# RL6678_IP_SVD register map
Vendor: Realtek
Registers are 32-bit, read-write, reset 0x0 unless marked. A register's access mark holds for its fields unless they carry their own. Offsets are from the block's base; [hi:lo] are bit positions; lines under a group give offsets from that group; {n}, {i} and the like mark numbered series.

## MEM_CTRL
Base 0x42009200
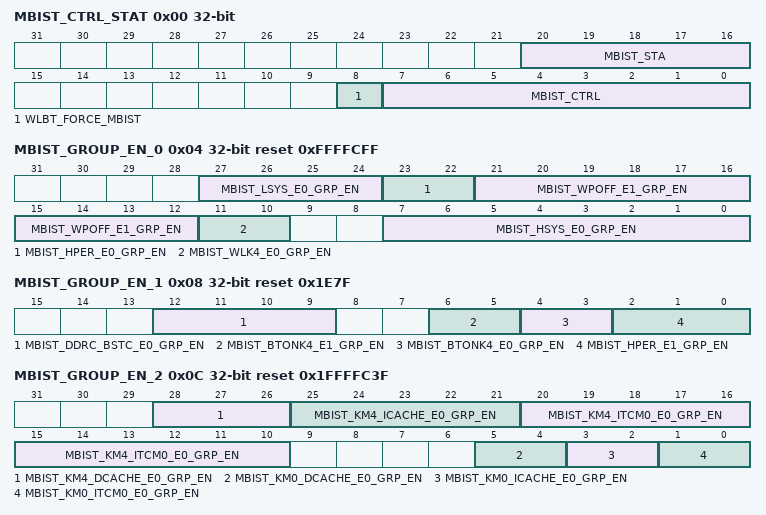
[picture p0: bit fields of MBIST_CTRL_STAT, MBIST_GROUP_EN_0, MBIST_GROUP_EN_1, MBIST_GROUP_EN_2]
0x00 MBIST_CTRL_STAT access per field — MEMx MBIST control and status register
  [20:16] MBIST_STA ro — [16]: MBIST START_PAUSE [17]: MBIST NRML_DONE [18]: MBIST NRML_FAIL [19]: MBIST DRF_DONE [20]: MBIST DRF_FAIL
  [8] WLBT_FORCE_MBIST rw — select power mode signal of BT and WL memory when mbist testing: 1: reg 0: from BT/WL
  [7:0] MBIST_CTRL rw — [0]: MBIST_CLK_EN [1]: MBIST_RSTB_ALL: MEMx bist reset of all memorys. [3:2]: MBIST_MSEL_ALL MEMx mbist method selection of all memorys 2'b01: normal 2'b10: drf 2'b11: normal+drf [4]: MBIST_RESUME [5]: MBIST_RESUME_PS [6]: MBIST_DYN_READ_EN [7]: MBIST_PHYCLK_STOP
0x04 MBIST_GROUP_EN_0 reset 0xFFFFCFF — MEMx system memory group enable control register
  [27:24] MBIST_LSYS_E0_GRP_EN, [23:22] MBIST_HPER_E0_GRP_EN, [21:12] MBIST_WPOFF_E1_GRP_EN, [11:10] MBIST_WLK4_E0_GRP_EN, [7:0] MBIST_HSYS_E0_GRP_EN
0x08 MBIST_GROUP_EN_1 reset 0x1E7F — MEMx system meory group enable control register
  [12:9] MBIST_DDRC_BSTC_E0_GRP_EN, [6:5] MBIST_BTONK4_E1_GRP_EN, [4:3] MBIST_BTONK4_E0_GRP_EN, [2:0] MBIST_HPER_E1_GRP_EN
0x0C MBIST_GROUP_EN_2 reset 0x1FFFFC3F — MEMx system meory group enable control register
  [28:26] MBIST_KM4_DCACHE_E0_GRP_EN, [25:21] MBIST_KM4_ICACHE_E0_GRP_EN, [20:10] MBIST_KM4_ITCM0_E0_GRP_EN, [5:4] MBIST_KM0_DCACHE_E0_GRP_EN, [3:2] MBIST_KM0_ICACHE_E0_GRP_EN, [1:0] MBIST_KM0_ITCM0_E0_GRP_EN
0x10 MBIST_RSTB_0 reset 0xFFFFFFFF — MEMx MBIST reset control register [31:0]
  [31:0] MBIST_RSTB_31_0 — valid MBIST_RSTB range is [MBIST_GRP_NUM-1:0]. MBIST_GRP_NUM = 34, they are: *system memory group: 25 *bt special group: 1 *km0_e0 group : 3 *km4_e0 group : 3 *mipic_e0 group: 2
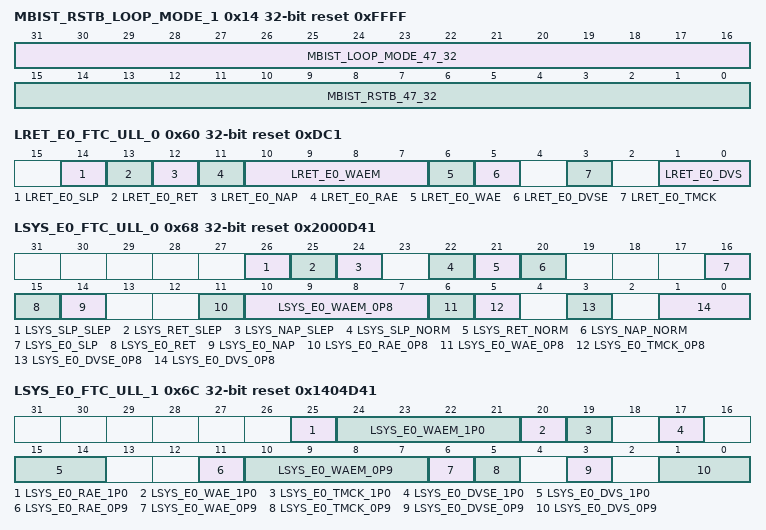
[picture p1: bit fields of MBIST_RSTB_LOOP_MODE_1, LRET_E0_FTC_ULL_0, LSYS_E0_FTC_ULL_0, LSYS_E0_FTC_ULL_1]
0x14 MBIST_RSTB_LOOP_MODE_1 reset 0xFFFF — MEMx MBIST reset & loop_mode control register [47:32]
  [31:16] MBIST_LOOP_MODE_47_32 — valid MBIST_LOOP_MODE range is [MBIST_GRP_NUM-1:0].
  [15:0] MBIST_RSTB_47_32 — valid MBIST_RSTB range is [MBIST_GRP_NUM-1:0]. MBIST_GRP_NUM = 34, they are: *system memory group: 25 *bt special group: 1 *km0_e0 group : 3 *km4_e0 group : 3 *mipic_e0 group: 2
0x18 MBIST_LOOP_MODE_0 — MEMx MBIST loop mode controlregister
  [31:0] MBIST_LOOP_MODE_31_0 — valid MBIST_LOOP_MODE range is [MBIST_GRP_NUM-1:0]
0x1C MBIST_MSEL_0 reset 0xFFFFFFFF — MEMx MBIST method select register control bit[31:0]
  [31:0] MBIST_MSEL_31_0 — valid MBIST_MSEL range is [MBIST_GRP_NUM*2-1:0] MBIST_MSEL[2*X] = 1 eanbles BIST_MODE mode of groupX; MBIST_MSEL[2*X+1] = 1 eanbles DRF_BIST_MODE mode of groupX.
0x20 MBIST_MSEL_1 reset 0xFFFFFFFF — MEMx MBIST method select control register bit[63:32]
  [31:0] MBIST_MSEL_63_32 — valid MBIST_MSEL range is [MBIST_GRP_NUM*2-1:0] MBIST_MSEL[2*X] = 1 eanbles BIST_MODE mode of groupX; MBIST_MSEL[2*X+1] = 1 eanbles DRF_BIST_MODE mode of groupX.
0x24 MBIST_MSEL_2 reset 0xFFFFFFFF — MEMx MBIST method select control register bit[95:64]
  [31:0] MBIST_MSEL_95_64 — valid MBIST_MSEL range is [MBIST_GRP_NUM*2-1:0] MBIST_MSEL[2*X] = 1 eanbles BIST_MODE mode of groupX; MBIST_MSEL[2*X+1] = 1 eanbles DRF_BIST_MODE mode of groupX.
0x28 MBIST_START_PAUSE_STAT ro — MEMx mbist start pause status register
0x2C MBIST_DONE_STAT ro — MEMx MBIST done status register
{0x30+4i} MBIST_FAIL_NRML_STAT_{i} ro (i=0..2) — MEMx MBIST fail status register bit[{32i+31}:{32i}]
  [31:0] MBIST_FAIL_NRML_STAT_{32i+31}_{32i}
{0x3C+4i} MBIST_FAIL_DRF_STAT_{i} ro (i=0..2) — MEMx drf mbist fail status register bit[{32i+31}:{32i}]
  [31:0] MBIST_FAIL_DRF_STAT_{32i+31}_{32i}
0x48 ROM_LSPMC_E0_MISR_DOUT_0 ro — lspmc_e0 ROM mbist misr_dout[31:0]
  [31:0] ROM_LSPMC_E0_MISR_DOUT_31_0
0x4C ROM_LSPMC_E0_MISR_DOUT_1 ro — lspmc_e0 ROM mbist misr_dout[35:32]
  [3:0] ROM_LSPMC_E0_MISR_DOUT_35_32
0x50 ROM_AONPMC_E0_MISR_DOUT_0 ro — aonpmc_e0 ROM mbist misr_dout[31:0]
  [31:0] ROM_AONPMC_E0_MISR_DOUT_31_0
0x54 ROM_AONPMC_E0_MISR_DOUT_1 ro — aonpmc_e0 ROM mbist misr_dout[35:32]
  [3:0] ROM_AONPMC_E0_MISR_DOUT_35_32
0x58 ROM_CA7BOOT_E0_MISR_DOUT_0 ro — catboot_e0 ROM mbist misr_dout[31:0]
  [31:0] ROM_CA7BOOT_E0_MISR_DOUT_31_0
0x5C ROM_CA7BOOT_E0_MISR_DOUT_1 ro — catboot_e0 ROM mbist misr_dout[63:32]
  [31:0] ROM_CA7BOOT_E0_MISR_DOUT_63_32
0x60 LRET_E0_FTC_ULL_0 reset 0xDC1
  [14] LRET_E0_SLP — SW control: SW can write this register when chip is ACTIVE. HW control: will load LSYS_SLP_SLEP to this reg when chip goes to SLEP ; will load LSYS_SLP_NORM to this reg when chip goes to ACTIVE ; SLP = 1 : Shut-down mode
  [13] LRET_E0_RET — SW control: SW can write this register when chip is ACTIVE. HW control: will load LSYS_RET_SLEP to this reg when chip goes to SLEP ; will load LSYS_RET_NORM to this reg when chip goes to ACTIVE ; RET = 1 : Deep-sleep mode
  [12] LRET_E0_NAP — SW control: SW can write this register when chip is ACTIVE. HW control: will load LSYS_NAP_SLEP to this reg when chip goes to SLEP ; will load LSYS_NAP_NORM to this reg when chip goes to ACTIVE ; NAP = 1 : Light-sleep mode
  [11] LRET_E0_RAE — FTC_ULL+ SPRAM RAE, 0.8V
  [10:7] LRET_E0_WAEM — FTC_ULL+ SPRAM WAEM[3:2] @0.8V *WAEM[3:0] @ 0.8V: 4'b1011 *WAEM[3:0] @ 0.9v/1.0v: 4'b1001
  [6] LRET_E0_WAE — FTC_ULL+ SPRAM WAE, 0.8V
  [5] LRET_E0_DVSE — FTC_ULL+ SPRAM DVSE
  [3] LRET_E0_TMCK — FTC_ULL+ SPRAM TMCK
  [1:0] LRET_E0_DVS — FTC_ULL+ DVS default is 2'b01 in 0.8v/0.9v,1.0v.
0x68 LSYS_E0_FTC_ULL_0 reset 0x2000D41
  [26] LSYS_SLP_SLEP — deep sleep mode. SW control: set this register before chip goes to SLEP HW control: when chip goes to SLEP,PMC will load this reg value to LSYS_E0_SLP/LRET_E0_SLP/KM0_DCACHE_DATA_SLP/KM0_DCACHE_TAG_SLP/KM0_ICACHE_DATA_SLP/KM0_ICACHE_TAG_SLP (set_pst_lmem=1 & val_pst_lmem=0)
  [25] LSYS_RET_SLEP — deep sleep mode. SW control: set this register before chip goes to SLEP HW control: when chip goes to SLEP,PMC will load this reg value to LSYS_E0_RET/LRET_E0_RET/KM0_DCACHE_DATA_RET/KM0_DCACHE_TAG_RET/KM0_ICACHE_DATA_RET/KM0_ICACHE_TAG_RET (set_pst_lmem=1 & val_pst_lmem=0)
  [24] LSYS_NAP_SLEP — deep sleep mode. SW control: set this register before chip goes to SLEP HW control: when chip goes to SLEP,PMC will load this reg value to LSYS_E0_NAP/LRET_E0_NAP/KM0_DCACHE_DATA_NAP/KM0_DCACHE_TAG_NAP/KM0_ICACHE_DATA_NAP/KM0_ICACHE_TAG_NAP (set_pst_lmem=1 & val_pst_lmem=0)when chip goes to SLEP
  [22] LSYS_SLP_NORM — Active mode. HW control: when chip goes to ACTIVE, PMC will load this reg value to LSYS_E0_SLP/LRET_E0_SLP/KM0_DCACHE_DATA_SLP/KM0_DCACHE_TAG_SLP/KM0_ICACHE_DATA_SLP/KM0_ICACHE_TAG_SLP (set_pst_lmem=1 & val_pst_lmem=1).
  [21] LSYS_RET_NORM — Active mode. HW control: when chip goes to ACTIVE, PMC will load this reg value to LSYS_E0_RET/LRET_E0_RET/KM0_DCACHE_DATA_RET/KM0_DCACHE_TAG_RET/KM0_ICACHE_DATA_RET/KM0_ICACHE_TAG_RET (set_pst_lmem=1 & val_pst_lmem=1).
  [20] LSYS_NAP_NORM — Active mode. HW control: when chip goes to ACTIVE, PMC will load this reg value to LSYS_E0_NAP/LRET_E0_NAP/KM0_DCACHE_DATA_NAP/KM0_DCACHE_TAG_NAP/KM0_ICACHE_DATA_NAP/KM0_ICACHE_TAG_NAP (set_pst_lmem=1 & val_pst_lmem=1).
  [16] LSYS_E0_SLP — SW control: SW can write this register when chip is ACTIVE. HW control: will load LSYS_SLP_SLEP to this reg when chip goes to SLEP ; will load LSYS_SLP_NORM to this reg when chip goes to ACTIVE ; SLP = 1 : Shut-down mode
  [15] LSYS_E0_RET — SW control: SW can write this register when chip is ACTIVE. HW control: will load LSYS_RET_SLEP to this reg when chip goes to SLEP ; will load LSYS_RET_NORM to this reg when chip goes to ACTIVE ; RET = 1 : Deep-sleep mode
  [14] LSYS_E0_NAP — SW control: SW can write this register when chip is ACTIVE. HW control: will load LSYS_NAP_SLEP to this reg when chip goes to SLEP ; will load LSYS_NAP_NORM to this reg when chip goes to ACTIVE ; NAP = 1 : Light-sleep mode
  [11] LSYS_E0_RAE_0P8 — FTC_ULL+ SPRAM RAE, @0.8V
  [10:7] LSYS_E0_WAEM_0P8 — FTC_ULL+ SPRAM WAEM[3:2], @0.8V *WAEM[3:0] @ 0.8V: 4'b1010 *WAEM[3:0] @ 0.9v/1.0v: 4'b1010
  [6] LSYS_E0_WAE_0P8 — FTC_ULL+ SPRAM WAE, @0.8V
  [5] LSYS_E0_TMCK_0P8 — FTC_ULL+ SPRAM TMCK
  [3] LSYS_E0_DVSE_0P8 — FTC_ULL+ SPRAM DVSE
  [1:0] LSYS_E0_DVS_0P8 — FTC_ULL+ DVS default is 2'b01 in 0.8v/0.9v,1.0v.
0x6C LSYS_E0_FTC_ULL_1 reset 0x1404D41
  [25] LSYS_E0_RAE_1P0 — FTC_ULL+ SPRAM RAE @1.0V
  [24:21] LSYS_E0_WAEM_1P0 — FTC_ULL+ SPRAM WAEM[1:0] @0.9V
  [20] LSYS_E0_WAE_1P0 — *WAEM[3:0] @ 0.8V: 4'b1010
  [19] LSYS_E0_TMCK_1P0 — *WAEM[3:0] @ 0.9v/1.0v: 4'b1010
  [17] LSYS_E0_DVSE_1P0 — FTC_ULL+ SPRAM DVSE
  [15:14] LSYS_E0_DVS_1P0 — FTC_ULL+ DVS default is 2'b01 in 0.8v/0.9v,1.0v.
  [11] LSYS_E0_RAE_0P9 — FTC_ULL+ SPRAM RAE @0.9V
  [10:7] LSYS_E0_WAEM_0P9 — FTC_ULL+ SPRAM WAEM[1:0] @0.9V *WAEM[3:0] @ 0.8V: 4'b1010 *WAEM[3:0] @ 0.9v/1.0v: 4'b1010
  [6] LSYS_E0_WAE_0P9 — FTC_ULL+ SPRAM WAE @0.9V
  [5] LSYS_E0_TMCK_0P9 — FTC_ULL+ SPRAM TMCK
  [3] LSYS_E0_DVSE_0P9 — FTC_ULL+ SPRAM DVSE
  [1:0] LSYS_E0_DVS_0P9 — FTC_ULL+ DVS default is 2'b01 in 0.8v/0.9v,1.0v.
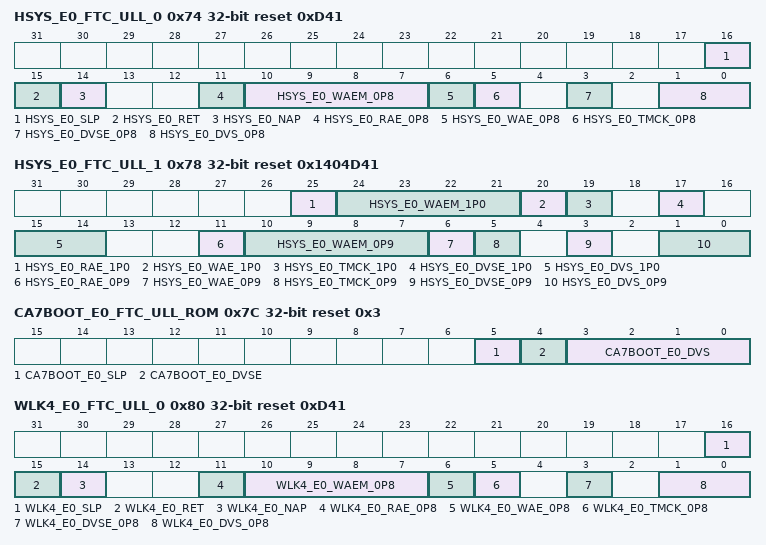
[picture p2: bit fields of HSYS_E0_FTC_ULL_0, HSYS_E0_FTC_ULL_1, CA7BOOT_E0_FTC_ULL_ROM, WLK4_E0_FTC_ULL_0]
0x74 HSYS_E0_FTC_ULL_0 reset 0xD41
  [16] HSYS_E0_SLP — FTC_ULL+ SPRAM SLP
  [15] HSYS_E0_RET — FTC_ULL+ SPRAM RET
  [14] HSYS_E0_NAP — FTC_ULL+ SPRAM NAP
  [11] HSYS_E0_RAE_0P8 — FTC_ULL+ SPRAM RAE, @0.8V
  [10:7] HSYS_E0_WAEM_0P8 — FTC_ULL+ SPRAM WAEM[3:2], @0.8V *WAEM[3:0] @ 0.8V: 4'b1010 *WAEM[3:0] @ 0.9v/1.0v: 4'b1010
  [6] HSYS_E0_WAE_0P8 — FTC_ULL+ SPRAM WAE, @0.8V
  [5] HSYS_E0_TMCK_0P8 — FTC_ULL+ SPRAM TMCK
  [3] HSYS_E0_DVSE_0P8 — FTC_ULL+ SPRAM DVSE
  [1:0] HSYS_E0_DVS_0P8 — FTC_ULL+ DVS default is 2'b01 in 0.8v/0.9v,1.0v.
0x78 HSYS_E0_FTC_ULL_1 reset 0x1404D41
  [25] HSYS_E0_RAE_1P0 — FTC_ULL+ SPRAM RAE @1.0V
  [24:21] HSYS_E0_WAEM_1P0 — FTC_ULL+ SPRAM WAEM[3:2] @1.0V *WAEM[3:0] @ 0.8V: 4'b1010 *WAEM[3:0] @ 0.9v/1.0v: 4'b1010
  [20] HSYS_E0_WAE_1P0 — FTC_ULL+ SPRAM WAE @1.0V
  [19] HSYS_E0_TMCK_1P0 — FTC_ULL+ SPRAM TMCK
  [17] HSYS_E0_DVSE_1P0 — FTC_ULL+ SPRAM DVSE
  [15:14] HSYS_E0_DVS_1P0 — FTC_ULL+ DVS default is 2'b01 in 0.8v/0.9v,1.0v.
  [11] HSYS_E0_RAE_0P9 — FTC_ULL+ SPRAM RAE @0.9V
  [10:7] HSYS_E0_WAEM_0P9 — FTC_ULL+ SPRAM WAEM[1:0] @0.9V *WAEM[3:0] @ 0.8V: 4'b1010 *WAEM[3:0] @ 0.9v/1.0v: 4'b1010
  [6] HSYS_E0_WAE_0P9 — FTC_ULL+ SPRAM WAE @0.9V
  [5] HSYS_E0_TMCK_0P9 — FTC_ULL+ SPRAM TMCK
  [3] HSYS_E0_DVSE_0P9 — FTC_ULL+ SPRAM DVSE
  [1:0] HSYS_E0_DVS_0P9 — FTC_ULL+ DVS default is 2'b01 in 0.8v/0.9v,1.0v.
0x7C CA7BOOT_E0_FTC_ULL_ROM reset 0x3
  [5] CA7BOOT_E0_SLP — FTC_ULL+ SPROM, PG bit2, not used in btrom
  [4] CA7BOOT_E0_DVSE — FTC_ULL+ SPROM
  [3:0] CA7BOOT_E0_DVS — FTC_ULL+ SPROM
0x80 WLK4_E0_FTC_ULL_0 reset 0xD41
  [16] WLK4_E0_SLP — FTC_ULL+ SPRAM SLP
  [15] WLK4_E0_RET — FTC_ULL+ SPRAM RET
  [14] WLK4_E0_NAP — FTC_ULL+ SPRAM NAP
  [11] WLK4_E0_RAE_0P8 — FTC_ULL+ SPRAM RAE, @0.8V
  [10:7] WLK4_E0_WAEM_0P8 — FTC_ULL+ SPRAM WAEM[3:2], @0.8V *WAEM[3:0] @ 0.8V: 4'b1010 *WAEM[3:0] @ 0.9v/1.0v: 4'b1010
  [6] WLK4_E0_WAE_0P8 — FTC_ULL+ SPRAM WAE, @0.8V
  [5] WLK4_E0_TMCK_0P8 — FTC_ULL+ SPRAM TMCK
  [3] WLK4_E0_DVSE_0P8 — FTC_ULL+ SPRAM DVSE
  [1:0] WLK4_E0_DVS_0P8 — FTC_ULL+ DVS default is 2'b01 in 0.8v/0.9v,1.0v.
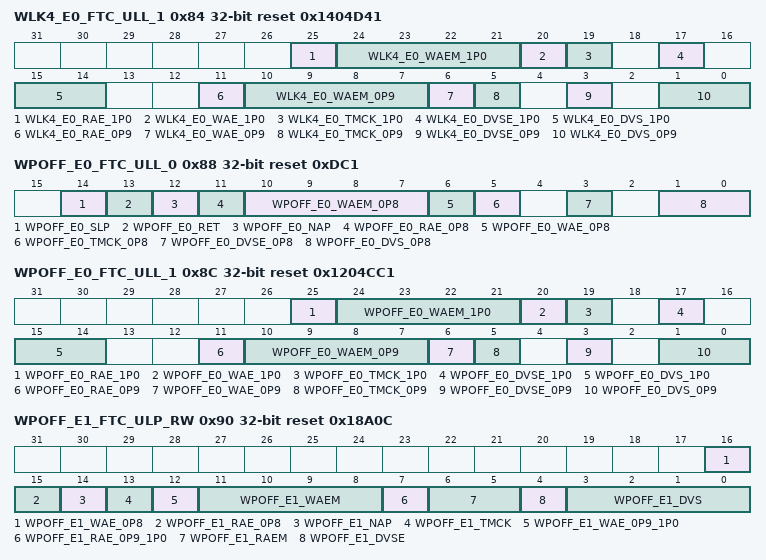
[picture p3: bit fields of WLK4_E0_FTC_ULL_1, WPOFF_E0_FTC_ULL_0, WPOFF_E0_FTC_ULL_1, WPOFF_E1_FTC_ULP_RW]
0x84 WLK4_E0_FTC_ULL_1 reset 0x1404D41
  [25] WLK4_E0_RAE_1P0 — FTC_ULL+ SPRAM RAE @1.0V
  [24:21] WLK4_E0_WAEM_1P0 — FTC_ULL+ SPRAM WAEM[3:2], @0.8V *WAEM[3:0] @ 0.8V: 4'b1010 *WAEM[3:0] @ 0.9v/1.0v: 4'b1010
  [20] WLK4_E0_WAE_1P0 — FTC_ULL+ SPRAM WAE @1.0V
  [19] WLK4_E0_TMCK_1P0 — FTC_ULL+ SPRAM TMCK
  [17] WLK4_E0_DVSE_1P0 — FTC_ULL+ SPRAM DVSE
  [15:14] WLK4_E0_DVS_1P0 — FTC_ULL+ DVS default is 2'b01 in 0.8v/0.9v,1.0v.
  [11] WLK4_E0_RAE_0P9 — FTC_ULL+ SPRAM RAE @0.9V
  [10:7] WLK4_E0_WAEM_0P9 — FTC_ULL+ SPRAM WAEM[3:2], @0.8V *WAEM[3:0] @ 0.8V: 4'b1010 *WAEM[3:0] @ 0.9v/1.0v: 4'b1010
  [6] WLK4_E0_WAE_0P9 — FTC_ULL+ SPRAM WAE @0.9V
  [5] WLK4_E0_TMCK_0P9 — FTC_ULL+ SPRAM TMCK
  [3] WLK4_E0_DVSE_0P9 — FTC_ULL+ SPRAM DVSE
  [1:0] WLK4_E0_DVS_0P9 — FTC_ULL+ DVS default is 2'b01 in 0.8v/0.9v,1.0v.
0x88 WPOFF_E0_FTC_ULL_0 reset 0xDC1
  [14] WPOFF_E0_SLP — FTC_ULL+ SPRAM SLP
  [13] WPOFF_E0_RET — FTC_ULL+ SPRAM RET
  [12] WPOFF_E0_NAP — FTC_ULL+ SPRAM NAP
  [11] WPOFF_E0_RAE_0P8 — FTC_ULL+ SPRAM RAE, @0.8V
  [10:7] WPOFF_E0_WAEM_0P8 — FTC_ULL+ SPRAM WAEM[3:2], @0.8V *WAEM[3:0] @ 0.8V: 4'b1011 *WAEM[3:0] @ 0.9v/1.0v: 4'b1001
  [6] WPOFF_E0_WAE_0P8 — FTC_ULL+ SPRAM WAE, @0.8V
  [5] WPOFF_E0_TMCK_0P8 — FTC_ULL+ SPRAM TMCK
  [3] WPOFF_E0_DVSE_0P8 — FTC_ULL+ SPRAM DVSE
  [1:0] WPOFF_E0_DVS_0P8 — FTC_ULL+ DVS default is 2'b01 in 0.8v/0.9v,1.0v.
0x8C WPOFF_E0_FTC_ULL_1 reset 0x1204CC1
  [25] WPOFF_E0_RAE_1P0 — FTC_ULL+ SPRAM RAE @1.0V
  [24:21] WPOFF_E0_WAEM_1P0 — FTC_ULL+ SPRAM WAEM[3:2] @1.0V *WAEM[3:0] @ 0.8V: 4'b1011 *WAEM[3:0] @ 0.9v/1.0v: 4'b1001
  [20] WPOFF_E0_WAE_1P0 — FTC_ULL+ SPRAM WAE @1.0V
  [19] WPOFF_E0_TMCK_1P0 — FTC_ULL+ SPRAM TMCK
  [17] WPOFF_E0_DVSE_1P0 — FTC_ULL+ SPRAM DVSE
  [15:14] WPOFF_E0_DVS_1P0 — FTC_ULL+ DVS default is 2'b01 in 0.8v/0.9v,1.0v.
  [11] WPOFF_E0_RAE_0P9 — FTC_ULL+ SPRAM RAE @0.9V
  [10:7] WPOFF_E0_WAEM_0P9 — FTC_ULL+ SPRAM WAEM[1:0] @0.9V *WAEM[3:0] @ 0.8V: 4'b1011 *WAEM[3:0] @ 0.9v/1.0v: 4'b1001
  [6] WPOFF_E0_WAE_0P9 — FTC_ULL+ SPRAM WAE @0.9V
  [5] WPOFF_E0_TMCK_0P9 — FTC_ULL+ SPRAM TMCK
  [3] WPOFF_E0_DVSE_0P9 — FTC_ULL+ SPRAM DVSE
  [1:0] WPOFF_E0_DVS_0P9 — FTC_ULL+ DVS default is 2'b01 in 0.8v/0.9v,1.0v.
0x90 WPOFF_E1_FTC_ULP_RW reset 0x18A0C
  [16] WPOFF_E1_WAE_0P8 — FTC_ULP_SPRAM_RW,0.8V WAE=1: Turn on the write assist circuit.
  [15] WPOFF_E1_RAE_0P8 — FTC_ULP_SPRAM_RW,0.8V RAE=1: Turn on the read assist circuit.
  [14] WPOFF_E1_NAP — FTC_ULP_SPRAM_RW: pg_b0 CSB=1 & NAP=1 reduce peripheral power. Cell array's data retained.
  [13] WPOFF_E1_TMCK — FTC_ULP_SPRAM_RW Internal timing bypass signal. TMCK=1: WL pulse will be controlled by the clock duty cycle. TMCK=0: default value, RAM access normally.
  [12] WPOFF_E1_WAE_0P9_1P0 — FTC_ULP_SPRAM_RW WAE=1: Turn on the write assist circuit. WAE=0: Turn off the write assist circuit.
  [11:8] WPOFF_E1_WAEM — FTC_ULP_SPRAM_RW WAEM[3:2] controls the write assist circuit timing margin when WAE=1. WAEM[3:2]=00: turn off the time margin of the write assist circuit. WAEM[3:2]=01: Lossest timing margin WAEM[3:2]=10: WAEM[3:2]=11: Tightest timing margin. WAEM[1:0] controls the write assist circuit voltage margin when WAE=1. WAEM[1:0]=00: Turn off the voltage margin of the write assist circuit WAEM[1:0]=01: Minimum voltage margin WAEM[1:0]=10: WAEM[1:0]=11: Maximum voltage margin.
  [7] WPOFF_E1_RAE_0P9_1P0 — FTC_ULP_SPRAM_RW RAE=1: turn on the read assist circuit. RAE=0: turn off the read assist circuit.
  [6:5] WPOFF_E1_RAEM — FTC_ULP_SPRAM_RW adjust the margin of read assist circuit when RAE=1. RAEM=00: default WL voltage drop RAEM=01 RAEM=10 RAEM=11: maximum WL voltage drop
  [4] WPOFF_E1_DVSE — FTC_ULP_SPRAM_RW DVSE=1: delay option enable. DVSE=0: delay option disable.
  [3:0] WPOFF_E1_DVS — FTC_ULP_SPRAM_RW DVS[0] controls the SRAM sensing pulse when DVSE=1. DVS[0]=1: short pulse width DVS[0]=0: long pulse width dvs[3:1] is delay option control words when DVSE=1. DVS[3:1] = 000: loosest margin. DVS[3:1] = 001 DVS[3:1] = 010 DVS[3:1] = 011 ...
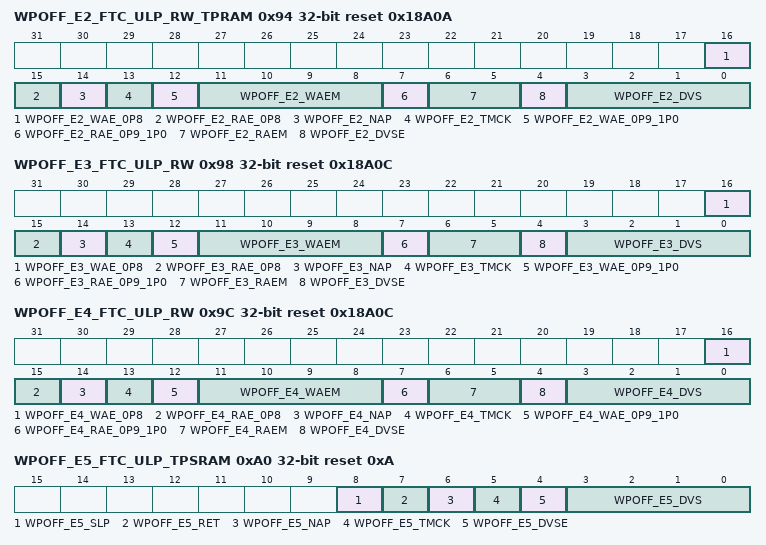
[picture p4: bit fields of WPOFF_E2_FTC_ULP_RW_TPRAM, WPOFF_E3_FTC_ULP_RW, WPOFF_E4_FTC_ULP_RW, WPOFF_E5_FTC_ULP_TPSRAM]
0x94 WPOFF_E2_FTC_ULP_RW_TPRAM reset 0x18A0A
  [16] WPOFF_E2_WAE_0P8 — FTC_ULP_SPRAM_RW,0.8V WAE=1: Turn on the write assist circuit.
  [15] WPOFF_E2_RAE_0P8 — FTC_ULP_SPRAM_RW,0.8V RAE=1: Turn on the read assist circuit.
  [14] WPOFF_E2_NAP — FTC_ULP_RW_TPRAM:pg_b0 CSA(B)=1 & NAP=1 reduce peripheral power. Cell array's data retained.
  [13] WPOFF_E2_TMCK — FTC_ULP_RW_TPRAM
  [12] WPOFF_E2_WAE_0P9_1P0 — FTC_ULP_RW_TPRAM
  [11:8] WPOFF_E2_WAEM — FTC_ULP_RW_TPRAM
  [7] WPOFF_E2_RAE_0P9_1P0 — FTC_ULP_RW_TPRAM
  [6:5] WPOFF_E2_RAEM — FTC_ULP_RW_TPRAM
  [4] WPOFF_E2_DVSE — FTC_ULP_RW_TPRAM
  [3:0] WPOFF_E2_DVS — FTC_ULP_RW_TPRAM
0x98 WPOFF_E3_FTC_ULP_RW reset 0x18A0C
  [16] WPOFF_E3_WAE_0P8 — FTC_ULP_SPRAM_RW,0.8V WAE=1: Turn on the write assist circuit.
  [15] WPOFF_E3_RAE_0P8 — FTC_ULP_SPRAM_RW,0.8V RAE=1: Turn on the read assist circuit.
  [14] WPOFF_E3_NAP — FTC_ULP_RW_RF: pg_b0 CSB=1 & NAP=1 reduce peripheral power. Cell array's data retained.
  [13] WPOFF_E3_TMCK — FTC_ULP_RW_RF Internal timing bypass signal. TMCK=1: WL pulse will be controlled by the clock duty cycle. TMCK=0: default value, RAM access normally.
  [12] WPOFF_E3_WAE_0P9_1P0 — FTC_ULP_RW_RF WAE=1: Turn on the write assist circuit. WAE=0: Turn off the write assist circuit.
  [11:8] WPOFF_E3_WAEM — FTC_ULP_RW_RF WAEM[3:2] controls the write assist circuit timing margin when WAE=1. WAEM[3:2]=00: turn off the time margin of the write assist circuit. WAEM[3:2]=01: Lossest timing margin WAEM[3:2]=10: WAEM[3:2]=11: Tightest timing margin. WAEM[1:0] controls the write assist circuit voltage margin when WAE=1. WAEM[1:0]=00: Turn off the voltage margin of the write assist circuit WAEM[1:0]=01: Minimum voltage margin WAEM[1:0]=10: WAEM[1:0]=11: Maximum voltage margin.
  [7] WPOFF_E3_RAE_0P9_1P0 — FTC_ULP_RW_RF RAE=1: turn on the read assist circuit. RAE=0: turn off the read assist circuit.
  [6:5] WPOFF_E3_RAEM — FTC_ULP_RW_RF adjust the margin of read assist circuit when RAE=1. RAEM=00: default WL voltage drop RAEM=01 RAEM=10 RAEM=11: maximum WL voltage drop
  [4] WPOFF_E3_DVSE — FTC_ULP_RW_RF DVSE=1: delay option enable. DVSE=0: delay option disable.
  [3:0] WPOFF_E3_DVS — FTC_ULP_RW_RF DVS[0] controls the SRAM sensing pulse when DVSE=1. DVS[0]=1: short pulse width DVS[0]=0: long pulse width dvs[3:1] is delay option control words when DVSE=1. DVS[3:1] = 000: loosest margin. DVS[3:1] = 001 DVS[3:1] = 010 DVS[3:1] = 011 ...
0x9C WPOFF_E4_FTC_ULP_RW reset 0x18A0C
  [16] WPOFF_E4_WAE_0P8 — FTC_ULP_SPRAM_RW,0.8V WAE=1: Turn on the write assist circuit.
  [15] WPOFF_E4_RAE_0P8 — FTC_ULP_SPRAM_RW,0.8V RAE=1: Turn on the read assist circuit.
  [14] WPOFF_E4_NAP — FTC_ULP_RW_RF: pg_b0 CSB=1 & NAP=1 reduce peripheral power. Cell array's data retained.
  [13] WPOFF_E4_TMCK — FTC_ULP_RW_RF Internal timing bypass signal. TMCK=1: WL pulse will be controlled by the clock duty cycle. TMCK=0: default value, RAM access normally.
  [12] WPOFF_E4_WAE_0P9_1P0 — FTC_ULP_RW_RF WAE=1: Turn on the write assist circuit. WAE=0: Turn off the write assist circuit.
  [11:8] WPOFF_E4_WAEM — FTC_ULP_RW_RF WAEM[3:2] controls the write assist circuit timing margin when WAE=1. WAEM[3:2]=00: turn off the time margin of the write assist circuit. WAEM[3:2]=01: Lossest timing margin WAEM[3:2]=10: WAEM[3:2]=11: Tightest timing margin. WAEM[1:0] controls the write assist circuit voltage margin when WAE=1. WAEM[1:0]=00: Turn off the voltage margin of the write assist circuit WAEM[1:0]=01: Minimum voltage margin WAEM[1:0]=10: WAEM[1:0]=11: Maximum voltage margin.
  [7] WPOFF_E4_RAE_0P9_1P0 — FTC_ULP_RW_RF RAE=1: turn on the read assist circuit. RAE=0: turn off the read assist circuit.
  [6:5] WPOFF_E4_RAEM — FTC_ULP_RW_RF adjust the margin of read assist circuit when RAE=1. RAEM=00: default WL voltage drop RAEM=01 RAEM=10 RAEM=11: maximum WL voltage drop
  [4] WPOFF_E4_DVSE — FTC_ULP_RW_RF DVSE=1: delay option enable. DVSE=0: delay option disable.
  [3:0] WPOFF_E4_DVS — FTC_ULP_RW_RF DVS[0] controls the SRAM sensing pulse when DVSE=1. DVS[0]=1: short pulse width DVS[0]=0: long pulse width dvs[3:1] is delay option control words when DVSE=1. DVS[3:1] = 000: loosest margin. DVS[3:1] = 001 DVS[3:1] = 010 DVS[3:1] = 011 ...
0xA0 WPOFF_E5_FTC_ULP_TPSRAM reset 0xA
  [8] WPOFF_E5_SLP
  [7] WPOFF_E5_RET
  [6] WPOFF_E5_NAP
  [5] WPOFF_E5_TMCK — FTC_ULP_2P_RF
  [4] WPOFF_E5_DVSE — FTC_ULP_2P_RF
  [3:0] WPOFF_E5_DVS — FTC_ULP_2P_RF
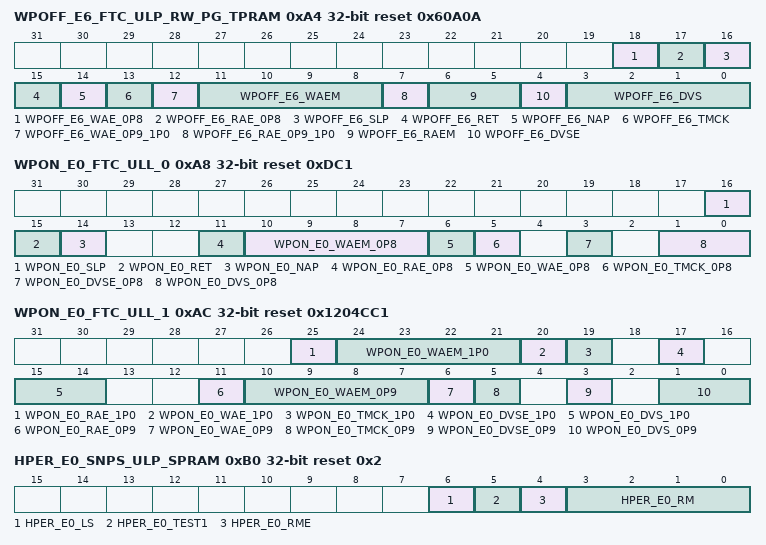
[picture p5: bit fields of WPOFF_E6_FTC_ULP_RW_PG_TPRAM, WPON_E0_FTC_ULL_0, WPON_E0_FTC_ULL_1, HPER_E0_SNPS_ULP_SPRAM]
0xA4 WPOFF_E6_FTC_ULP_RW_PG_TPRAM reset 0x60A0A
  [18] WPOFF_E6_WAE_0P8 — FTC_ULP_SPRAM_RW,0.8V WAE=1: Turn on the write assist circuit.
  [17] WPOFF_E6_RAE_0P8 — FTC_ULP_SPRAM_RW,0.8V RAE=1: Turn on the read assist circuit.
  [16] WPOFF_E6_SLP — FTC_ULP_RW_TPRAM:pg_b2
  [15] WPOFF_E6_RET — FTC_ULP_RW_TPRAM:pg_b1
  [14] WPOFF_E6_NAP — FTC_ULP_RW_TPRAM:pg_b0 CSA(B)=1 & NAP=1 reduce peripheral power. Cell array's data retained.
  [13] WPOFF_E6_TMCK — FTC_ULP_RW_TPRAM
  [12] WPOFF_E6_WAE_0P9_1P0 — FTC_ULP_RW_TPRAM
  [11:8] WPOFF_E6_WAEM — FTC_ULP_RW_TPRAM
  [7] WPOFF_E6_RAE_0P9_1P0 — FTC_ULP_RW_TPRAM
  [6:5] WPOFF_E6_RAEM — FTC_ULP_RW_TPRAM
  [4] WPOFF_E6_DVSE — FTC_ULP_RW_TPRAM
  [3:0] WPOFF_E6_DVS — FTC_ULP_RW_TPRAM
0xA8 WPON_E0_FTC_ULL_0 reset 0xDC1
  [16] WPON_E0_SLP — FTC_ULL+ SPRAM SLP
  [15] WPON_E0_RET — FTC_ULL+ SPRAM RET
  [14] WPON_E0_NAP — FTC_ULL+ SPRAM NAP
  [11] WPON_E0_RAE_0P8 — FTC_ULL+ SPRAM RAE, @0.8V
  [10:7] WPON_E0_WAEM_0P8 — FTC_ULL+ SPRAM WAEM[3:2], @0.8V *WAEM[3:0] @ 0.8V: 4'b1011 *WAEM[3:0] @ 0.9v/1.0v: 4'b1001
  [6] WPON_E0_WAE_0P8 — FTC_ULL+ SPRAM WAE, @0.8V
  [5] WPON_E0_TMCK_0P8 — FTC_ULL+ SPRAM TMCK
  [3] WPON_E0_DVSE_0P8 — FTC_ULL+ SPRAM DVSE
  [1:0] WPON_E0_DVS_0P8 — FTC_ULL+ DVS default is 2'b01 in 0.8v/0.9v,1.0v.
0xAC WPON_E0_FTC_ULL_1 reset 0x1204CC1
  [25] WPON_E0_RAE_1P0 — FTC_ULL+ SPRAM RAE @1.0V
  [24:21] WPON_E0_WAEM_1P0 — FTC_ULL+ SPRAM WAEM[3:2] @1.0V *WAEM[3:0] @ 0.8V: 4'b1011 *WAEM[3:0] @ 0.9v/1.0v: 4'b1001
  [20] WPON_E0_WAE_1P0 — FTC_ULL+ SPRAM WAE @1.0V
  [19] WPON_E0_TMCK_1P0 — FTC_ULL+ SPRAM TMCK
  [17] WPON_E0_DVSE_1P0 — FTC_ULL+ SPRAM DVSE
  [15:14] WPON_E0_DVS_1P0 — FTC_ULL+ DVS default is 2'b01 in 0.8v/0.9v,1.0v.
  [11] WPON_E0_RAE_0P9 — FTC_ULL+ SPRAM RAE @0.9V
  [10:7] WPON_E0_WAEM_0P9 — FTC_ULL+ SPRAM WAEM[1:0] @0.9V *WAEM[3:0] @ 0.8V: 4'b1011 *WAEM[3:0] @ 0.9v/1.0v: 4'b1001
  [6] WPON_E0_WAE_0P9 — FTC_ULL+ SPRAM WAE @0.9V
  [5] WPON_E0_TMCK_0P9 — FTC_ULL+ SPRAM TMCK
  [3] WPON_E0_DVSE_0P9 — FTC_ULL+ SPRAM DVSE
  [1:0] WPON_E0_DVS_0P9 — FTC_ULL+ DVS default is 2'b01 in 0.8v/0.9v,1.0v.
0xB0 HPER_E0_SNPS_ULP_SPRAM reset 0x2
  [6] HPER_E0_LS — SNPS_ULP_SPRAM: pg_b0 LS=1 ram is in light sleep mode, memory array's data retained.
  [5] HPER_E0_TEST1 — SNPS_ULP_SPRAM Test1 pin to bypass self-timed circuit. The external clock controls the read and write controls. The self time bypass mode occpuied High phase of external clock. The self time bypass mode may used to determine time margin of internal self-timed circuitry.
  [4] HPER_E0_RME — SNPS_ULP_SPRAM RME selects between internal and external RM[2:0] settings, RM[3] is not controlled by RME. RME=1: select external RM[2:0] RME=0: select internal RM[2:0]
  [3:0] HPER_E0_RM — SNPS_ULP_SPRAM RM[1:0] are used to trade-off betwwen speed and robustness(yield). 2'b11: fast 2'b10: default 2'b01: slow 2'b00: VDDmin RM[3:2] are used for test purpose.
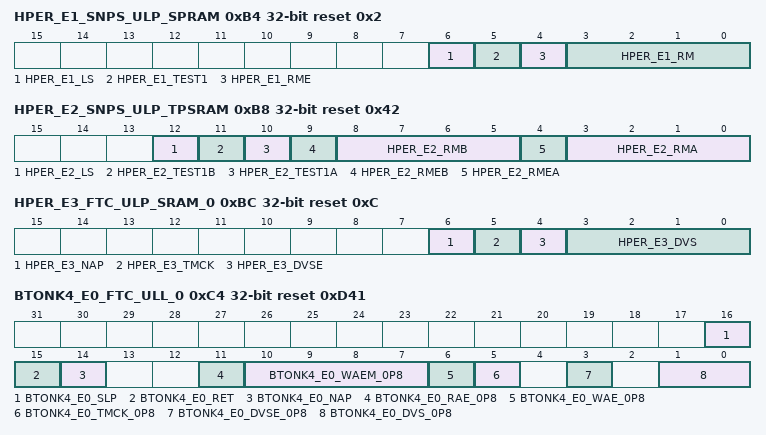
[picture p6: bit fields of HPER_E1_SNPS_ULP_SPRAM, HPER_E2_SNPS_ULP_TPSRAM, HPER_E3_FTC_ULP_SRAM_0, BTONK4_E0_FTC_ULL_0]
0xB4 HPER_E1_SNPS_ULP_SPRAM reset 0x2
  [6] HPER_E1_LS — SNPS_ULP_SPRAM: pg_b0 LS=1 ram is in light sleep mode, memory array's data retained.
  [5] HPER_E1_TEST1 — SNPS_ULP_SPRAM Test1 pin to bypass self-timed circuit. The external clock controls the read and write controls. The self time bypass mode occpuied High phase of external clock. The self time bypass mode may used to determine time margin of internal self-timed circuitry.
  [4] HPER_E1_RME — SNPS_ULP_SPRAM RME selects between internal and external RM[2:0] settings, RM[3] is not controlled by RME. RME=1: select external RM[2:0] RME=0: select internal RM[2:0]
  [3:0] HPER_E1_RM — SNPS_ULP_SPRAM RM[1:0] are used to trade-off betwwen speed and robustness(yield). 2'b11: fast 2'b10: default 2'b01: slow 2'b00: VDDmin RM[3:2] are used for test purpose.
0xB8 HPER_E2_SNPS_ULP_TPSRAM reset 0x42
  [12] HPER_E2_LS — SNPS_ULP_TPRAM: pg_b0 LS=1 ram is in light sleep mode, memory array's data retained.
  [11] HPER_E2_TEST1B — SNPS_ULP_TPRAM
  [10] HPER_E2_TEST1A — SNPS_ULP_TPRAM
  [9] HPER_E2_RMEB — SNPS_ULP_TPRAM
  [8:5] HPER_E2_RMB — SNPS_ULP_TPRAM
  [4] HPER_E2_RMEA — SNPS_ULP_TPRAM
  [3:0] HPER_E2_RMA — SNPS_ULP_TPRAM
0xBC HPER_E3_FTC_ULP_SRAM_0 reset 0xC
  [6] HPER_E3_NAP — FTC_ULP SPRAM without R/W assist & without power gating
  [5] HPER_E3_TMCK
  [4] HPER_E3_DVSE
  [3:0] HPER_E3_DVS
0xC4 BTONK4_E0_FTC_ULL_0 reset 0xD41
  [16] BTONK4_E0_SLP — FTC_ULL+ SPRAM SLP
  [15] BTONK4_E0_RET — FTC_ULL+ SPRAM RET
  [14] BTONK4_E0_NAP — FTC_ULL+ SPRAM NAP
  [11] BTONK4_E0_RAE_0P8 — FTC_ULL+ SPRAM RAE, @0.8V
  [10:7] BTONK4_E0_WAEM_0P8 — FTC_ULL+ SPRAM WAEM[3:2], @0.8V *WAEM[3:0] @ 0.8V: 4'b1010 *WAEM[3:0] @ 0.9v/1.0v: 4'b1010
  [6] BTONK4_E0_WAE_0P8 — FTC_ULL+ SPRAM WAE, @0.8V
  [5] BTONK4_E0_TMCK_0P8 — FTC_ULL+ SPRAM TMCK
  [3] BTONK4_E0_DVSE_0P8 — FTC_ULL+ SPRAM DVSE
  [1:0] BTONK4_E0_DVS_0P8 — FTC_ULL+ DVS default is 2'b01 in 0.8v/0.9v,1.0v.
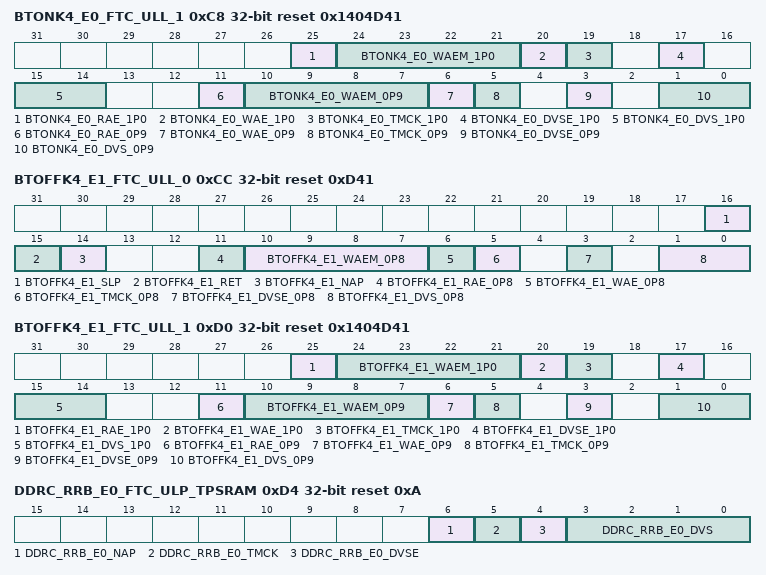
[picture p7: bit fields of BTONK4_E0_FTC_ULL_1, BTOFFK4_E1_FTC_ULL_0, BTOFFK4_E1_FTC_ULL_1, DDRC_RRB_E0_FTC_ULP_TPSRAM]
0xC8 BTONK4_E0_FTC_ULL_1 reset 0x1404D41
  [25] BTONK4_E0_RAE_1P0 — FTC_ULL+ SPRAM RAE @1.0V
  [24:21] BTONK4_E0_WAEM_1P0 — FTC_ULL+ SPRAM WAEM[3:2] @1.0V *WAEM[3:0] @ 0.8V: 4'b1010 *WAEM[3:0] @ 0.9v/1.0v: 4'b1010
  [20] BTONK4_E0_WAE_1P0 — FTC_ULL+ SPRAM WAE @1.0V
  [19] BTONK4_E0_TMCK_1P0 — FTC_ULL+ SPRAM TMCK
  [17] BTONK4_E0_DVSE_1P0 — FTC_ULL+ SPRAM DVSE
  [15:14] BTONK4_E0_DVS_1P0 — FTC_ULL+ DVS default is 2'b01 in 0.8v/0.9v,1.0v.
  [11] BTONK4_E0_RAE_0P9 — FTC_ULL+ SPRAM RAE @0.9V
  [10:7] BTONK4_E0_WAEM_0P9 — FTC_ULL+ SPRAM WAEM[1:0] @0.9V *WAEM[3:0] @ 0.8V: 4'b1010 *WAEM[3:0] @ 0.9v/1.0v: 4'b1010
  [6] BTONK4_E0_WAE_0P9 — FTC_ULL+ SPRAM WAE @0.9V
  [5] BTONK4_E0_TMCK_0P9 — FTC_ULL+ SPRAM TMCK
  [3] BTONK4_E0_DVSE_0P9 — FTC_ULL+ SPRAM DVSE
  [1:0] BTONK4_E0_DVS_0P9 — FTC_ULL+ DVS default is 2'b01 in 0.8v/0.9v,1.0v.
0xCC BTOFFK4_E1_FTC_ULL_0 reset 0xD41
  [16] BTOFFK4_E1_SLP — FTC_ULL+ SPRAM SLP
  [15] BTOFFK4_E1_RET — FTC_ULL+ SPRAM RET
  [14] BTOFFK4_E1_NAP — FTC_ULL+ SPRAM NAP
  [11] BTOFFK4_E1_RAE_0P8 — FTC_ULL+ SPRAM RAE, @0.8V
  [10:7] BTOFFK4_E1_WAEM_0P8 — FTC_ULL+ SPRAM WAEM[3:2], @0.8V *WAEM[3:0] @ 0.8V: 4'b1010 *WAEM[3:0] @ 0.9v/1.0v: 4'b1010
  [6] BTOFFK4_E1_WAE_0P8 — FTC_ULL+ SPRAM WAE, @0.8V
  [5] BTOFFK4_E1_TMCK_0P8 — FTC_ULL+ SPRAM TMCK
  [3] BTOFFK4_E1_DVSE_0P8 — FTC_ULL+ SPRAM DVSE
  [1:0] BTOFFK4_E1_DVS_0P8 — FTC_ULL+ DVS default is 2'b01 in 0.8v/0.9v,1.0v. FTC_ULL+ DVS default is 2'b01 in 0.8v/0.9v,1.0v.
0xD0 BTOFFK4_E1_FTC_ULL_1 reset 0x1404D41
  [25] BTOFFK4_E1_RAE_1P0 — FTC_ULL+ SPRAM RAE @1.0V
  [24:21] BTOFFK4_E1_WAEM_1P0 — FTC_ULL+ SPRAM WAEM[3:2] @1.0V *WAEM[3:0] @ 0.8V: 4'b1010 *WAEM[3:0] @ 0.9v/1.0v: 4'b1010
  [20] BTOFFK4_E1_WAE_1P0 — FTC_ULL+ SPRAM WAE @1.0V
  [19] BTOFFK4_E1_TMCK_1P0 — FTC_ULL+ SPRAM TMCK
  [17] BTOFFK4_E1_DVSE_1P0 — FTC_ULL+ SPRAM DVSE
  [15:14] BTOFFK4_E1_DVS_1P0 — FTC_ULL+ DVS default is 2'b01 in 0.8v/0.9v,1.0v.
  [11] BTOFFK4_E1_RAE_0P9 — FTC_ULL+ SPRAM RAE @0.9V
  [10:7] BTOFFK4_E1_WAEM_0P9 — FTC_ULL+ SPRAM WAEM[1:0] @0.9V *WAEM[3:0] @ 0.8V: 4'b1010 *WAEM[3:0] @ 0.9v/1.0v: 4'b1010
  [6] BTOFFK4_E1_WAE_0P9 — FTC_ULL+ SPRAM WAE @0.9V
  [5] BTOFFK4_E1_TMCK_0P9 — FTC_ULL+ SPRAM TMCK
  [3] BTOFFK4_E1_DVSE_0P9 — FTC_ULL+ SPRAM DVSE
  [1:0] BTOFFK4_E1_DVS_0P9 — FTC_ULL+ DVS default is 2'b01 in 0.8v/0.9v,1.0v.
0xD4 DDRC_RRB_E0_FTC_ULP_TPSRAM reset 0xA
  [6] DDRC_RRB_E0_NAP — FTC_ULP_2P_RF: pg_b0 CSA(B)=1 & NAP=1 reduce peripheral power. Cell array's data retained.
  [5] DDRC_RRB_E0_TMCK — FTC_ULP_2P_RF
  [4] DDRC_RRB_E0_DVSE — FTC_ULP_2P_RF
  [3:0] DDRC_RRB_E0_DVS — FTC_ULP_2P_RF
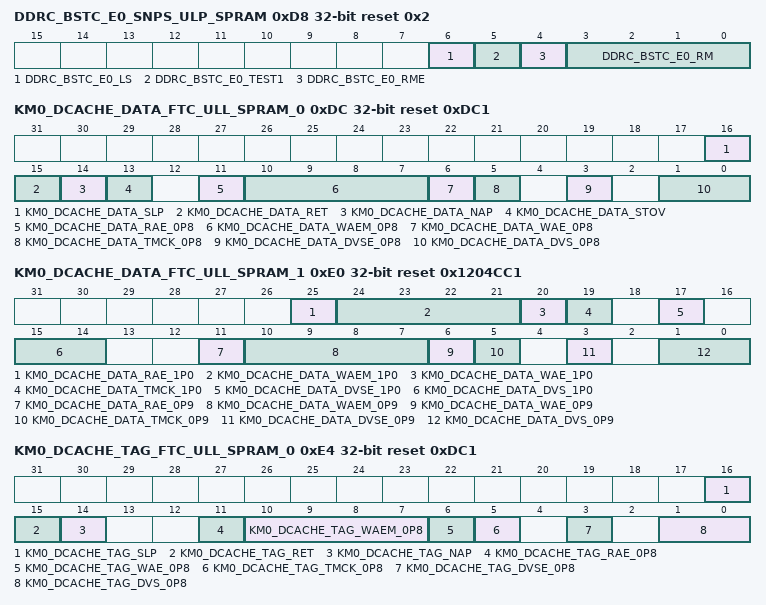
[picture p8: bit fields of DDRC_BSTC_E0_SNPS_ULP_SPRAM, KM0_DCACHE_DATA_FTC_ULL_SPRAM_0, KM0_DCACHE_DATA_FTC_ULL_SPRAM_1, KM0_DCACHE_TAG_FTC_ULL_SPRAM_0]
0xD8 DDRC_BSTC_E0_SNPS_ULP_SPRAM reset 0x2
  [6] DDRC_BSTC_E0_LS — SNPS_ULP_SPRAM: pg_b0 LS=1 ram is in light sleep mode, memory array's data retained.
  [5] DDRC_BSTC_E0_TEST1 — SNPS_ULP_SPRAM Test1 pin to bypass self-timed circuit. The external clock controls the read and write controls. The self time bypass mode occpuied High phase of external clock. The self time bypass mode may used to determine time margin of internal self-timed circuitry.
  [4] DDRC_BSTC_E0_RME — SNPS_ULP_SPRAM RME selects between internal and external RM[2:0] settings, RM[3] is not controlled by RME. RME=1: select external RM[2:0] RME=0: select internal RM[2:0]
  [3:0] DDRC_BSTC_E0_RM — SNPS_ULP_SPRAM RM[1:0] are used to trade: off betwwen speed and robustness(yield). 2'b11: fast 2'b10: default 2'b01: slow 2'b00: VDDmin RM[3:2] are used for test purpose.
0xDC KM0_DCACHE_DATA_FTC_ULL_SPRAM_0 reset 0xDC1
  [16] KM0_DCACHE_DATA_SLP — SW control: SW can write this register when chip is ACTIVE. ECO: add HW control: will load LSYS_SLP_SLEP to this reg when chip goes to SLEP ; will load LSYS_SLP_NORM to this reg when chip goes to ACTIVE ; SLP = 1 : Shut-down mode
  [15] KM0_DCACHE_DATA_RET — SW control: SW can write this register when chip is ACTIVE. ECO: add HW control: will load LSYS_RET_SLEP to this reg when chip goes to SLEP ; will load LSYS_RET_NORM to this reg when chip goes to ACTIVE ; RET = 1 : Deep-sleep mode
  [14] KM0_DCACHE_DATA_NAP — SW control: SW can write this register when chip is ACTIVE. ECO: add HW control: will load LSYS_NAP_SLEP to this reg when chip goes to SLEP ; will load LSYS_NAP_NORM to this reg when chip goes to ACTIVE ; NAP = 1 : Light-sleep mode
  [13] KM0_DCACHE_DATA_STOV — Not used.
  [11] KM0_DCACHE_DATA_RAE_0P8 — FTC_ULL+ SPRAM RAE, @0.8V
  [10:7] KM0_DCACHE_DATA_WAEM_0P8 — FTC_ULL+ SPRAM WAEM[3:2], @0.8V *WAEM[3:0] @ 0.8V: 4'b1011 *WAEM[3:0] @ 0.9v/1.0v: 4'b1001
  [6] KM0_DCACHE_DATA_WAE_0P8 — FTC_ULL+ SPRAM WAE, @0.8V
  [5] KM0_DCACHE_DATA_TMCK_0P8 — FTC_ULL+ SPRAM TMCK
  [3] KM0_DCACHE_DATA_DVSE_0P8 — FTC_ULL+ SPRAM DVSE
  [1:0] KM0_DCACHE_DATA_DVS_0P8 — FTC_ULL+ DVS default is 2'b01 in 0.8v/0.9v,1.0v. FTC_ULL+ DVS default is 2'b01 in 0.8v/0.9v,1.0v.
0xE0 KM0_DCACHE_DATA_FTC_ULL_SPRAM_1 reset 0x1204CC1
  [25] KM0_DCACHE_DATA_RAE_1P0 — FTC_ULL+ SPRAM RAE @1.0V
  [24:21] KM0_DCACHE_DATA_WAEM_1P0 — FTC_ULL+ SPRAM WAEM[3:2] @1.0V *WAEM[3:0] @ 0.8V: 4'b1011 *WAEM[3:0] @ 0.9v/1.0v: 4'b1001
  [20] KM0_DCACHE_DATA_WAE_1P0 — FTC_ULL+ SPRAM WAE @1.0V
  [19] KM0_DCACHE_DATA_TMCK_1P0 — FTC_ULL+ SPRAM TMCK
  [17] KM0_DCACHE_DATA_DVSE_1P0 — FTC_ULL+ SPRAM DVSE
  [15:14] KM0_DCACHE_DATA_DVS_1P0 — FTC_ULL+ DVS default is 2'b01 in 0.8v/0.9v,1.0v.
  [11] KM0_DCACHE_DATA_RAE_0P9 — FTC_ULL+ SPRAM RAE @0.9V
  [10:7] KM0_DCACHE_DATA_WAEM_0P9 — FTC_ULL+ SPRAM WAEM[1:0] @0.9V *WAEM[3:0] @ 0.8V: 4'b1011 *WAEM[3:0] @ 0.9v/1.0v: 4'b1001
  [6] KM0_DCACHE_DATA_WAE_0P9 — FTC_ULL+ SPRAM WAE @0.9V
  [5] KM0_DCACHE_DATA_TMCK_0P9 — FTC_ULL+ SPRAM TMCK
  [3] KM0_DCACHE_DATA_DVSE_0P9 — FTC_ULL+ SPRAM DVSE
  [1:0] KM0_DCACHE_DATA_DVS_0P9 — FTC_ULL+ DVS default is 2'b01 in 0.8v/0.9v,1.0v.
0xE4 KM0_DCACHE_TAG_FTC_ULL_SPRAM_0 reset 0xDC1
  [16] KM0_DCACHE_TAG_SLP — SW control: SW can write this register when chip is ACTIVE. ECO: add HW control: will load LSYS_SLP_SLEP to this reg when chip goes to SLEP ; will load LSYS_SLP_NORM to this reg when chip goes to ACTIVE ; SLP = 1 : Shut-down mode
  [15] KM0_DCACHE_TAG_RET — SW control: SW can write this register when chip is ACTIVE. ECO: add HW control: will load LSYS_RET_SLEP to this reg when chip goes to SLEP ; will load LSYS_RET_NORM to this reg when chip goes to ACTIVE ; RET = 1 : Deep-sleep mode
  [14] KM0_DCACHE_TAG_NAP — SW control: SW can write this register when chip is ACTIVE. ECO: add HW control: will load LSYS_NAP_SLEP to this reg when chip goes to SLEP ; will load LSYS_NAP_NORM to this reg when chip goes to ACTIVE ; NAP = 1 : Light-sleep mode
  [11] KM0_DCACHE_TAG_RAE_0P8 — FTC_ULL+ SPRAM RAE, @0.8V
  [10:7] KM0_DCACHE_TAG_WAEM_0P8 — FTC_ULL+ SPRAM WAEM[3:2], @0.8V *WAEM[3:0] @ 0.8V: 4'b1011 *WAEM[3:0] @ 0.9v/1.0v: 4'b1001
  [6] KM0_DCACHE_TAG_WAE_0P8 — FTC_ULL+ SPRAM WAE, @0.8V
  [5] KM0_DCACHE_TAG_TMCK_0P8 — FTC_ULL+ SPRAM TMCK
  [3] KM0_DCACHE_TAG_DVSE_0P8 — FTC_ULL+ SPRAM DVSE
  [1:0] KM0_DCACHE_TAG_DVS_0P8 — FTC_ULL+ DVS default is 2'b01 in 0.8v/0.9v,1.0v. FTC_ULL+ DVS default is 2'b01 in 0.8v/0.9v,1.0v.
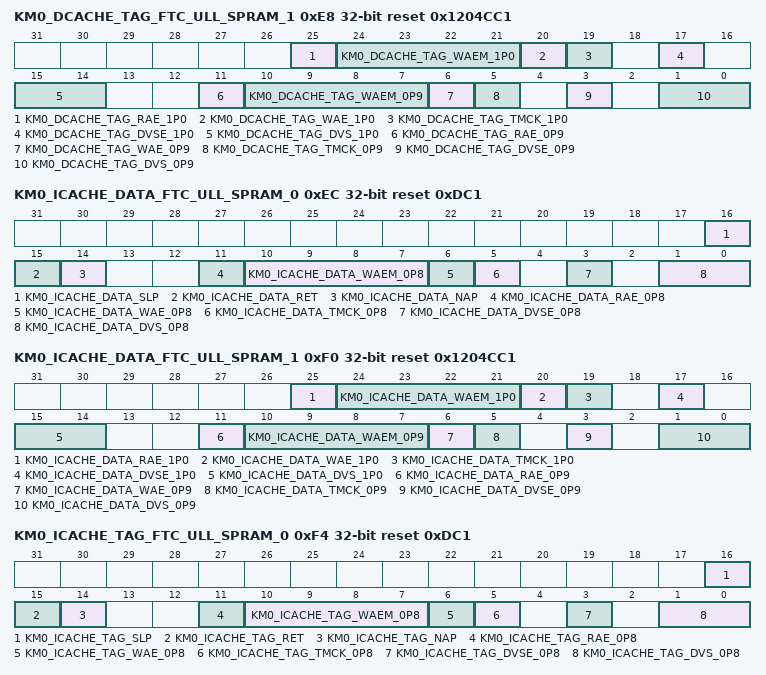
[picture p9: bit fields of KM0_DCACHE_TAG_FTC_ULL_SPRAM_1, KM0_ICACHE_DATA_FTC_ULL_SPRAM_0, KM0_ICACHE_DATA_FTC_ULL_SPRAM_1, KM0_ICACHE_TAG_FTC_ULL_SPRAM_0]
0xE8 KM0_DCACHE_TAG_FTC_ULL_SPRAM_1 reset 0x1204CC1
  [25] KM0_DCACHE_TAG_RAE_1P0 — FTC_ULL+ SPRAM RAE @1.0V
  [24:21] KM0_DCACHE_TAG_WAEM_1P0 — FTC_ULL+ SPRAM WAEM[3:2] @1.0V *WAEM[3:0] @ 0.8V: 4'b1011 *WAEM[3:0] @ 0.9v/1.0v: 4'b1001
  [20] KM0_DCACHE_TAG_WAE_1P0 — FTC_ULL+ SPRAM WAE @1.0V
  [19] KM0_DCACHE_TAG_TMCK_1P0 — FTC_ULL+ SPRAM TMCK
  [17] KM0_DCACHE_TAG_DVSE_1P0 — FTC_ULL+ SPRAM DVSE
  [15:14] KM0_DCACHE_TAG_DVS_1P0 — FTC_ULL+ DVS default is 2'b01 in 0.8v/0.9v,1.0v.
  [11] KM0_DCACHE_TAG_RAE_0P9 — FTC_ULL+ SPRAM RAE @0.9V
  [10:7] KM0_DCACHE_TAG_WAEM_0P9 — FTC_ULL+ SPRAM WAEM[1:0] @0.9V *WAEM[3:0] @ 0.8V: 4'b1011 *WAEM[3:0] @ 0.9v/1.0v: 4'b1001
  [6] KM0_DCACHE_TAG_WAE_0P9 — FTC_ULL+ SPRAM WAE @0.9V
  [5] KM0_DCACHE_TAG_TMCK_0P9 — FTC_ULL+ SPRAM TMCK
  [3] KM0_DCACHE_TAG_DVSE_0P9 — FTC_ULL+ SPRAM DVSE
  [1:0] KM0_DCACHE_TAG_DVS_0P9 — FTC_ULL+ DVS default is 2'b01 in 0.8v/0.9v,1.0v.
0xEC KM0_ICACHE_DATA_FTC_ULL_SPRAM_0 reset 0xDC1
  [16] KM0_ICACHE_DATA_SLP — SW control: SW can write this register when chip is ACTIVE. ECO: add HW control: will load LSYS_SLP_SLEP to this reg when chip goes to SLEP ; will load LSYS_SLP_NORM to this reg when chip goes to ACTIVE ; SLP = 1 : Shut-down mode
  [15] KM0_ICACHE_DATA_RET — SW control: SW can write this register when chip is ACTIVE. ECO: add HW control: will load LSYS_RET_SLEP to this reg when chip goes to SLEP ; will load LSYS_RET_NORM to this reg when chip goes to ACTIVE ; RET = 1 : Deep-sleep mode
  [14] KM0_ICACHE_DATA_NAP — SW control: SW can write this register when chip is ACTIVE. ECO: add HW control: will load LSYS_NAP_SLEP to this reg when chip goes to SLEP ; will load LSYS_NAP_NORM to this reg when chip goes to ACTIVE ; NAP = 1 : Light-sleep mode
  [11] KM0_ICACHE_DATA_RAE_0P8 — FTC_ULL+ SPRAM RAE, @0.8V
  [10:7] KM0_ICACHE_DATA_WAEM_0P8 — FTC_ULL+ SPRAM WAEM[3:2], @0.8V *WAEM[3:0] @ 0.8V: 4'b1011 *WAEM[3:0] @ 0.9v/1.0v: 4'b1001
  [6] KM0_ICACHE_DATA_WAE_0P8 — FTC_ULL+ SPRAM WAE, @0.8V
  [5] KM0_ICACHE_DATA_TMCK_0P8 — FTC_ULL+ SPRAM TMCK
  [3] KM0_ICACHE_DATA_DVSE_0P8 — FTC_ULL+ SPRAM DVSE
  [1:0] KM0_ICACHE_DATA_DVS_0P8 — FTC_ULL+ DVS default is 2'b01 in 0.8v/0.9v,1.0v. FTC_ULL+ DVS default is 2'b01 in 0.8v/0.9v,1.0v.
0xF0 KM0_ICACHE_DATA_FTC_ULL_SPRAM_1 reset 0x1204CC1
  [25] KM0_ICACHE_DATA_RAE_1P0 — FTC_ULL+ SPRAM RAE @1.0V
  [24:21] KM0_ICACHE_DATA_WAEM_1P0 — FTC_ULL+ SPRAM WAEM[3:2] @1.0V *WAEM[3:0] @ 0.8V: 4'b1011 *WAEM[3:0] @ 0.9v/1.0v: 4'b1001
  [20] KM0_ICACHE_DATA_WAE_1P0 — FTC_ULL+ SPRAM WAE @1.0V
  [19] KM0_ICACHE_DATA_TMCK_1P0 — FTC_ULL+ SPRAM TMCK
  [17] KM0_ICACHE_DATA_DVSE_1P0 — FTC_ULL+ SPRAM DVSE
  [15:14] KM0_ICACHE_DATA_DVS_1P0 — FTC_ULL+ DVS default is 2'b01 in 0.8v/0.9v,1.0v.
  [11] KM0_ICACHE_DATA_RAE_0P9 — FTC_ULL+ SPRAM RAE @0.9V
  [10:7] KM0_ICACHE_DATA_WAEM_0P9 — FTC_ULL+ SPRAM WAEM[1:0] @0.9V *WAEM[3:0] @ 0.8V: 4'b1011 *WAEM[3:0] @ 0.9v/1.0v: 4'b1001
  [6] KM0_ICACHE_DATA_WAE_0P9 — FTC_ULL+ SPRAM WAE @0.9V
  [5] KM0_ICACHE_DATA_TMCK_0P9 — FTC_ULL+ SPRAM TMCK
  [3] KM0_ICACHE_DATA_DVSE_0P9 — FTC_ULL+ SPRAM DVSE
  [1:0] KM0_ICACHE_DATA_DVS_0P9 — FTC_ULL+ DVS default is 2'b01 in 0.8v/0.9v,1.0v.
0xF4 KM0_ICACHE_TAG_FTC_ULL_SPRAM_0 reset 0xDC1
  [16] KM0_ICACHE_TAG_SLP — SW control: SW can write this register when chip is ACTIVE. ECO: add HW control: will load LSYS_SLP_SLEP to this reg when chip goes to SLEP ; will load LSYS_SLP_NORM to this reg when chip goes to ACTIVE ; SLP = 1 : Shut-down mode
  [15] KM0_ICACHE_TAG_RET — SW control: SW can write this register when chip is ACTIVE. ECO: add HW control: will load LSYS_RET_SLEP to this reg when chip goes to SLEP ; will load LSYS_RET_NORM to this reg when chip goes to ACTIVE ; RET = 1 : Deep-sleep mode
  [14] KM0_ICACHE_TAG_NAP — SW control: SW can write this register when chip is ACTIVE. ECO: add HW control: will load LSYS_NAP_SLEP to this reg when chip goes to SLEP ; will load LSYS_NAP_NORM to this reg when chip goes to ACTIVE ; NAP = 1 : Light-sleep mode
  [11] KM0_ICACHE_TAG_RAE_0P8 — FTC_ULL+ SPRAM RAE, @0.8V
  [10:7] KM0_ICACHE_TAG_WAEM_0P8 — FTC_ULL+ SPRAM WAEM[3:2], @0.8V *WAEM[3:0] @ 0.8V: 4'b1011 *WAEM[3:0] @ 0.9v/1.0v: 4'b1001
  [6] KM0_ICACHE_TAG_WAE_0P8 — FTC_ULL+ SPRAM WAE, @0.8V
  [5] KM0_ICACHE_TAG_TMCK_0P8 — FTC_ULL+ SPRAM TMCK
  [3] KM0_ICACHE_TAG_DVSE_0P8 — FTC_ULL+ SPRAM DVSE
  [1:0] KM0_ICACHE_TAG_DVS_0P8 — FTC_ULL+ DVS default is 2'b01 in 0.8v/0.9v,1.0v. FTC_ULL+ DVS default is 2'b01 in 0.8v/0.9v,1.0v.
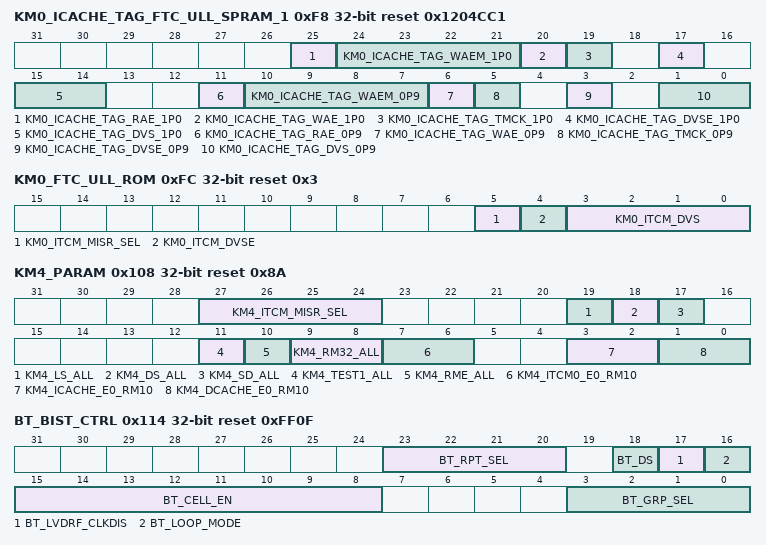
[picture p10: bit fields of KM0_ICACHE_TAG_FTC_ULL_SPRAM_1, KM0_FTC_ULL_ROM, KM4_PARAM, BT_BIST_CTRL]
0xF8 KM0_ICACHE_TAG_FTC_ULL_SPRAM_1 reset 0x1204CC1
  [25] KM0_ICACHE_TAG_RAE_1P0 — FTC_ULL+ SPRAM RAE @1.0V
  [24:21] KM0_ICACHE_TAG_WAEM_1P0 — FTC_ULL+ SPRAM WAEM[3:2] @1.0V *WAEM[3:0] @ 0.8V: 4'b1011 *WAEM[3:0] @ 0.9v/1.0v: 4'b1001
  [20] KM0_ICACHE_TAG_WAE_1P0 — FTC_ULL+ SPRAM WAE @1.0V
  [19] KM0_ICACHE_TAG_TMCK_1P0 — FTC_ULL+ SPRAM TMCK
  [17] KM0_ICACHE_TAG_DVSE_1P0 — FTC_ULL+ SPRAM DVSE
  [15:14] KM0_ICACHE_TAG_DVS_1P0 — FTC_ULL+ DVS default is 2'b01 in 0.8v/0.9v,1.0v.
  [11] KM0_ICACHE_TAG_RAE_0P9 — FTC_ULL+ SPRAM RAE @0.9V
  [10:7] KM0_ICACHE_TAG_WAEM_0P9 — FTC_ULL+ SPRAM WAEM[1:0] @0.9V *WAEM[3:0] @ 0.8V: 4'b1011 *WAEM[3:0] @ 0.9v/1.0v: 4'b1001
  [6] KM0_ICACHE_TAG_WAE_0P9 — FTC_ULL+ SPRAM WAE @0.9V
  [5] KM0_ICACHE_TAG_TMCK_0P9 — FTC_ULL+ SPRAM TMCK
  [3] KM0_ICACHE_TAG_DVSE_0P9 — FTC_ULL+ SPRAM DVSE
  [1:0] KM0_ICACHE_TAG_DVS_0P9 — FTC_ULL+ DVS default is 2'b01 in 0.8v/0.9v,1.0v.
0xFC KM0_FTC_ULL_ROM reset 0x3 — KM0 itcm parameter register
  [5] KM0_ITCM_MISR_SEL — select km0 itcm rom misr_dataout to register
  [4] KM0_ITCM_DVSE — for all rom memory
  [3:0] KM0_ITCM_DVS — for all rom memory
0x100 KM0_ITCM_MISR_DATA_0 ro
  [31:0] KM0_ITCM_MISR_DATA_31_0
0x104 KM0_ITCM_MISR_DATA_1 ro
  [31:0] KM0_ITCM_MISR_DATA_63_32
0x108 KM4_PARAM reset 0x8A — parameter for km4 memory
  [27:24] KM4_ITCM_MISR_SEL — select km4 itcm rom misr_dataout
  [19] KM4_LS_ALL — LS for all km4 memory. LS=1 ram is in light sleep mode, memory array's data retained.
  [18] KM4_DS_ALL
  [17] KM4_SD_ALL
  [11] KM4_TEST1_ALL — Test1 pin to bypass self-timed circuit. The external clock controls the read and write controls. The self time bypass mode occpuied High phase of external clock. The self time bypass mode may used to determine time margin of internal self-timed circuitry.
  [10] KM4_RME_ALL — RME for all km4 memory. RME selects between internal and external RM[2:0] settings, RM[3] is not controlled by RME. RME=1: select external RM[2:0] RME=0: select internal RM[2:0]
  [9:8] KM4_RM32_ALL — RM32 for all km4 memory. RM[3:2] are used for test purpose.
  [7:6] KM4_ITCM0_E0_RM10 — SNPS_ULP_SPROM, for KM4 itcm0~7 : RM[1:0] are used to trade-off betwwen speed and robustness(yield). 2'b11 - fast 2'b10 - default 2'b01 - slow 2'b00 - VDDmin RM[3:2] are used for test purpose.
  [3:2] KM4_ICACHE_E0_RM10 — SNPS_ULP_SPRAM RM[1:0] are used to trade-off betwwen speed and robustness(yield). 2'b11 - fast 2'b10 - default 2'b01 - slow 2'b00 - VDDmin RM[3:2] are used for test purpose.
  [1:0] KM4_DCACHE_E0_RM10 — SNPS_ULP_SPRAM RM[1:0] are used to trade-off betwwen speed and robustness(yield). 2'b11 - fast 2'b10 - default 2'b01 - slow 2'b00 - VDDmin RM[3:2] are used for test purpose.
0x10C KM4_ITCM_MISR_DATA_0 ro
  [31:0] KM4_ITCM_MISR_DATA_31_0
0x110 KM4_ITCM_MISR_DATA_1 ro
  [31:0] KM4_ITCM_MISR_DATA_63_32
0x114 BT_BIST_CTRL reset 0xFF0F — BT mbist control of BT
  [23:20] BT_RPT_SEL, [18] BT_DS, [17] BT_LVDRF_CLKDIS, [16] BT_LOOP_MODE, [15:8] BT_CELL_EN, [3:0] BT_GRP_SEL
0x118 BT_BIST_RPT ro — BT mbist report
0x11C BT_BIST_DONE ro — BT mbist done
0x120 BT_BIST_FAIL ro — BT mbist fail
0x124 BT_BIST_DRF_PAUSE ro — BT mbist drf start pause
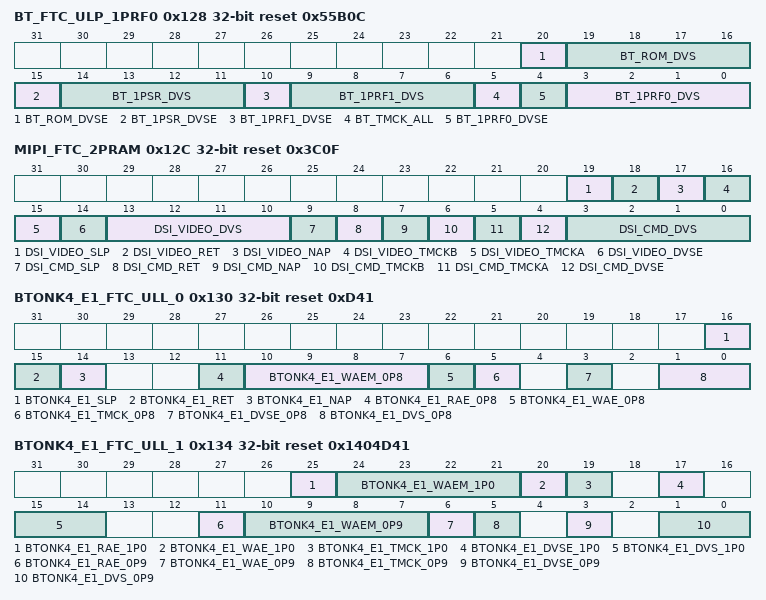
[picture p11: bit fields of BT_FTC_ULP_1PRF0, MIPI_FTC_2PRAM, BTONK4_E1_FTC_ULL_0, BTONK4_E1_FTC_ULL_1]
0x128 BT_FTC_ULP_1PRF0 reset 0x55B0C
  [20] BT_ROM_DVSE — connect to r_RME_ROM of BT. DVSE=1: delay option enable. DVSE=0: delay option disable.
  [19:16] BT_ROM_DVS — connect to r_RM_ROM of BT. DVS[0] controls the SRAM sensing pulse when DVSE=1. DVS[0]=1: short pulse width DVS[0]=0: long pulse width dvs[3:1] is delay option control words when DVSE=1. DVS[3:1] = 000: loosest margin. DVS[3:1] = 001 DVS[3:1] = 010 DVS[3:1] = 011 ...
  [15] BT_1PSR_DVSE — connect to r_RME_1PSR of BT. DVSE=1: delay option enable. DVSE=0: delay option disable.
  [14:11] BT_1PSR_DVS — connect to r_RM_1PSR of BT. DVS[0] controls the SRAM sensing pulse when DVSE=1. DVS[0]=1: short pulse width DVS[0]=0: long pulse width dvs[3:1] is delay option control words when DVSE=1. DVS[3:1] = 000: loosest margin. DVS[3:1] = 001 DVS[3:1] = 010 DVS[3:1] = 011 ...
  [10] BT_1PRF1_DVSE — connect to r_RME_1PRF1 of BT. DVSE=1: delay option enable. DVSE=0: delay option disable.
  [9:6] BT_1PRF1_DVS — connect to r_RM_1PRF1 of BT. DVS[0] controls the SRAM sensing pulse when DVSE=1. DVS[0]=1: short pulse width DVS[0]=0: long pulse width dvs[3:1] is delay option control words when DVSE=1. DVS[3:1] = 000: loosest margin. DVS[3:1] = 001 DVS[3:1] = 010 DVS[3:1] = 011 ...
  [5] BT_TMCK_ALL — connect to r_TEST1 of BT. Internal timing bypass signal. TMCK=1: WL pulse will be controlled by the clock duty cycle. TMCK=0: default value, RAM access normally.
  [4] BT_1PRF0_DVSE — connect to r_RME_1PRF0 of BT. DVSE=1: delay option enable. DVSE=0: delay option disable.
  [3:0] BT_1PRF0_DVS — connect to r_RM_1PRF0 of BT. DVS[0] controls the SRAM sensing pulse when DVSE=1. DVS[0]=1: short pulse width DVS[0]=0: long pulse width dvs[3:1] is delay option control words when DVSE=1. DVS[3:1] = 000: loosest margin. DVS[3:1] = 001 DVS[3:1] = 010 DVS[3:1] = 011 ...
0x12C MIPI_FTC_2PRAM reset 0x3C0F
  [19] DSI_VIDEO_SLP, [18] DSI_VIDEO_RET, [17] DSI_VIDEO_NAP, [16] DSI_VIDEO_TMCKB, [15] DSI_VIDEO_TMCKA, [14] DSI_VIDEO_DVSE, [13:10] DSI_VIDEO_DVS, [9] DSI_CMD_SLP, [8] DSI_CMD_RET, [7] DSI_CMD_NAP, [6] DSI_CMD_TMCKB, [5] DSI_CMD_TMCKA, [4] DSI_CMD_DVSE, [3:0] DSI_CMD_DVS
0x130 BTONK4_E1_FTC_ULL_0 reset 0xD41
  [16] BTONK4_E1_SLP — FTC_ULL+ SPRAM SLP
  [15] BTONK4_E1_RET — FTC_ULL+ SPRAM RET
  [14] BTONK4_E1_NAP — FTC_ULL+ SPRAM NAP
  [11] BTONK4_E1_RAE_0P8 — FTC_ULL+ SPRAM RAE, @0.8V
  [10:7] BTONK4_E1_WAEM_0P8 — FTC_ULL+ SPRAM WAEM[3:2], @0.8V *WAEM[3:0] @ 0.8V: 4'b1010 *WAEM[3:0] @ 0.9v/1.0v: 4'b1010
  [6] BTONK4_E1_WAE_0P8 — FTC_ULL+ SPRAM WAE, @0.8V
  [5] BTONK4_E1_TMCK_0P8 — FTC_ULL+ SPRAM TMCK
  [3] BTONK4_E1_DVSE_0P8 — FTC_ULL+ SPRAM DVSE
  [1:0] BTONK4_E1_DVS_0P8 — FTC_ULL+ DVS default is 2'b01 in 0.8v/0.9v,1.0v.
0x134 BTONK4_E1_FTC_ULL_1 reset 0x1404D41
  [25] BTONK4_E1_RAE_1P0 — FTC_ULL+ SPRAM RAE @1.0V
  [24:21] BTONK4_E1_WAEM_1P0 — FTC_ULL+ SPRAM WAEM[3:2] @1.0V *WAEM[3:0] @ 0.8V: 4'b1010 *WAEM[3:0] @ 0.9v/1.0v: 4'b1010
  [20] BTONK4_E1_WAE_1P0 — FTC_ULL+ SPRAM WAE @1.0V
  [19] BTONK4_E1_TMCK_1P0 — FTC_ULL+ SPRAM TMCK
  [17] BTONK4_E1_DVSE_1P0 — FTC_ULL+ SPRAM DVSE
  [15:14] BTONK4_E1_DVS_1P0 — FTC_ULL+ DVS default is 2'b01 in 0.8v/0.9v,1.0v.
  [11] BTONK4_E1_RAE_0P9 — FTC_ULL+ SPRAM RAE @0.9V
  [10:7] BTONK4_E1_WAEM_0P9 — FTC_ULL+ SPRAM WAEM[1:0] @0.9V *WAEM[3:0] @ 0.8V: 4'b1010 *WAEM[3:0] @ 0.9v/1.0v: 4'b1010
  [6] BTONK4_E1_WAE_0P9 — FTC_ULL+ SPRAM WAE @0.9V
  [5] BTONK4_E1_TMCK_0P9 — FTC_ULL+ SPRAM TMCK
  [3] BTONK4_E1_DVSE_0P9 — FTC_ULL+ SPRAM DVSE
  [1:0] BTONK4_E1_DVS_0P9 — FTC_ULL+ DVS default is 2'b01 in 0.8v/0.9v,1.0v.
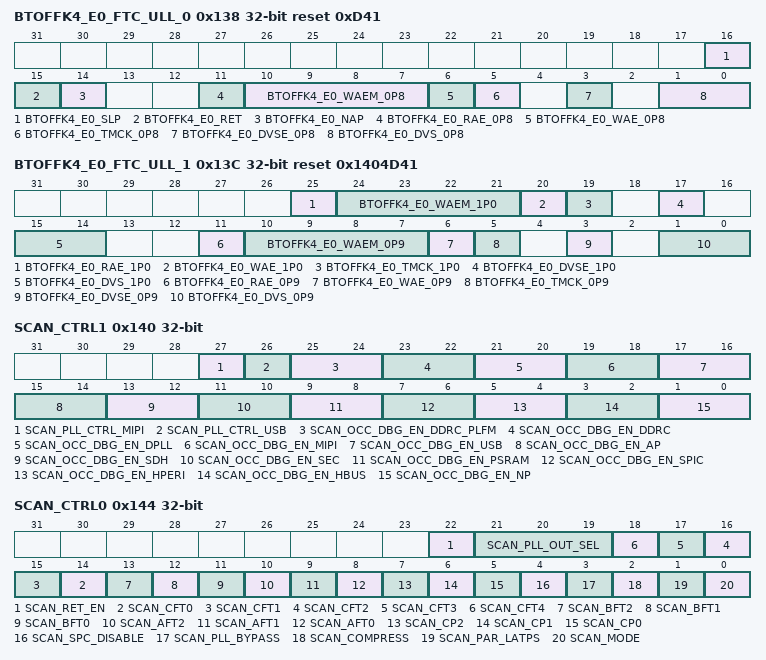
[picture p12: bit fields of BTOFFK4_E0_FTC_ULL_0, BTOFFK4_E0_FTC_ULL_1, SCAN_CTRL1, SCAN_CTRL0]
0x138 BTOFFK4_E0_FTC_ULL_0 reset 0xD41
  [16] BTOFFK4_E0_SLP — FTC_ULL+ SPRAM SLP
  [15] BTOFFK4_E0_RET — FTC_ULL+ SPRAM RET
  [14] BTOFFK4_E0_NAP — FTC_ULL+ SPRAM NAP
  [11] BTOFFK4_E0_RAE_0P8 — FTC_ULL+ SPRAM RAE, @0.8V
  [10:7] BTOFFK4_E0_WAEM_0P8 — FTC_ULL+ SPRAM WAEM[3:2], @0.8V *WAEM[3:0] @ 0.8V: 4'b1010 *WAEM[3:0] @ 0.9v/1.0v: 4'b1010
  [6] BTOFFK4_E0_WAE_0P8 — FTC_ULL+ SPRAM WAE, @0.8V
  [5] BTOFFK4_E0_TMCK_0P8 — FTC_ULL+ SPRAM TMCK
  [3] BTOFFK4_E0_DVSE_0P8 — FTC_ULL+ SPRAM DVSE
  [1:0] BTOFFK4_E0_DVS_0P8 — FTC_ULL+ DVS default is 2'b01 in 0.8v/0.9v,1.0v. FTC_ULL+ DVS default is 2'b01 in 0.8v/0.9v,1.0v.
0x13C BTOFFK4_E0_FTC_ULL_1 reset 0x1404D41
  [25] BTOFFK4_E0_RAE_1P0 — FTC_ULL+ SPRAM RAE @1.0V
  [24:21] BTOFFK4_E0_WAEM_1P0 — FTC_ULL+ SPRAM WAEM[3:2] @1.0V *WAEM[3:0] @ 0.8V: 4'b1010 *WAEM[3:0] @ 0.9v/1.0v: 4'b1010
  [20] BTOFFK4_E0_WAE_1P0 — FTC_ULL+ SPRAM WAE @1.0V
  [19] BTOFFK4_E0_TMCK_1P0 — FTC_ULL+ SPRAM TMCK
  [17] BTOFFK4_E0_DVSE_1P0 — FTC_ULL+ SPRAM DVSE
  [15:14] BTOFFK4_E0_DVS_1P0 — FTC_ULL+ DVS default is 2'b01 in 0.8v/0.9v,1.0v.
  [11] BTOFFK4_E0_RAE_0P9 — FTC_ULL+ SPRAM RAE @0.9V
  [10:7] BTOFFK4_E0_WAEM_0P9 — FTC_ULL+ SPRAM WAEM[1:0] @0.9V *WAEM[3:0] @ 0.8V: 4'b1010 *WAEM[3:0] @ 0.9v/1.0v: 4'b1010
  [6] BTOFFK4_E0_WAE_0P9 — FTC_ULL+ SPRAM WAE @0.9V
  [5] BTOFFK4_E0_TMCK_0P9 — FTC_ULL+ SPRAM TMCK
  [3] BTOFFK4_E0_DVSE_0P9 — FTC_ULL+ SPRAM DVSE
  [1:0] BTOFFK4_E0_DVS_0P9 — FTC_ULL+ DVS default is 2'b01 in 0.8v/0.9v,1.0v.
0x140 SCAN_CTRL1
  [27] SCAN_PLL_CTRL_MIPI, [26] SCAN_PLL_CTRL_USB, [25:24] SCAN_OCC_DBG_EN_DDRC_PLFM, [23:22] SCAN_OCC_DBG_EN_DDRC, [21:20] SCAN_OCC_DBG_EN_DPLL, [19:18] SCAN_OCC_DBG_EN_MIPI, [17:16] SCAN_OCC_DBG_EN_USB, [15:14] SCAN_OCC_DBG_EN_AP, [13:12] SCAN_OCC_DBG_EN_SDH, [11:10] SCAN_OCC_DBG_EN_SEC, [9:8] SCAN_OCC_DBG_EN_PSRAM, [7:6] SCAN_OCC_DBG_EN_SPIC, [5:4] SCAN_OCC_DBG_EN_HPERI, [3:2] SCAN_OCC_DBG_EN_HBUS, [1:0] SCAN_OCC_DBG_EN_NP
0x144 SCAN_CTRL0 access per field
  [22] SCAN_RET_EN rw — scan retention test enable
  [21:19] SCAN_PLL_OUT_SEL rw — scan pll out sel: 2'b000: nppll out 2'b001: wlpll out 2'b010: appll out 2'b011: usb0 pll out 2'b100: usb1 pll out 2'b101: mipi pll out 2'b110: dpll out
  [n+14] SCAN_CFT{n} rw (n=0..4) — scan QFN88 package ft mode{n}
  [13] SCAN_BFT2 rw — scan QFN144 NON-MCM package ft mode2
  [12] SCAN_BFT1 rw — scan QFN144 NON-MCM package ft mode1
  [11] SCAN_BFT0 rw — scan QFN144 NON-MCM package ft mode0
  [10] SCAN_AFT2 rw — scan QFN144 MCM package ft mode2
  [9] SCAN_AFT1 rw — scan QFN144 MCM package ft mode1
  [8] SCAN_AFT0 rw — scan QFN144 MCM package ft mode0
  [7] SCAN_CP2 rw — scan cp mode2
  [6] SCAN_CP1 rw — scan cp mode1
  [5] SCAN_CP0 rw — scan cp mode0
  [4] SCAN_SPC_DISABLE rw
  [3] SCAN_PLL_BYPASS rw
  [2] SCAN_COMPRESS rw
  [1] SCAN_PAR_LATPS wo — scan latch up pulse
  [0] SCAN_MODE wo — scan mode pulse
